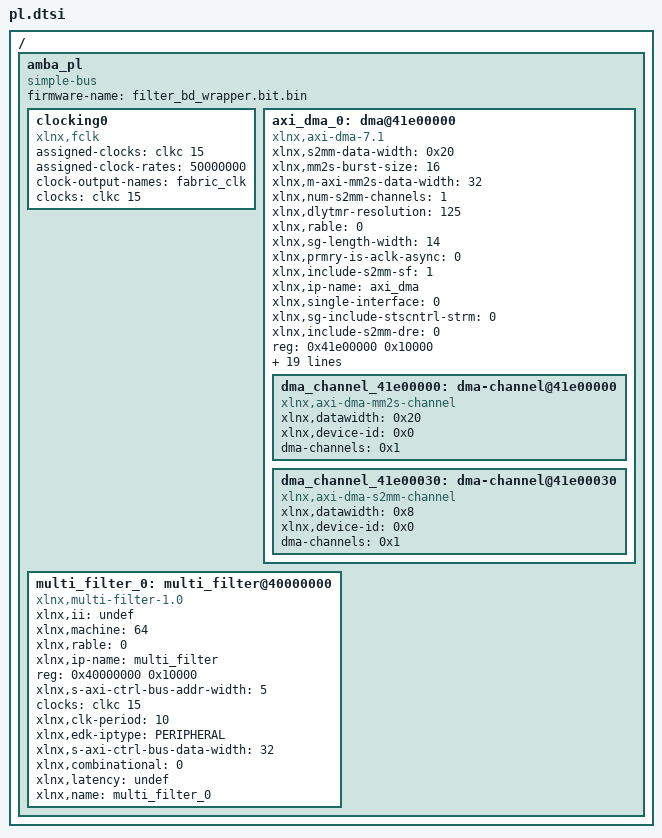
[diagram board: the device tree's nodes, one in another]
/ {
	amba_pl: amba_pl {
		ranges;
		compatible = "simple-bus";
		#address-cells = <1>;
		#size-cells = <1>;
		firmware-name = "filter_bd_wrapper.bit.bin";
		clocking0: clocking0 {
			compatible = "xlnx,fclk";
			assigned-clocks = <&clkc 15>;
			assigned-clock-rates = <50000000>;
			#clock-cells = <0>;
			clock-output-names = "fabric_clk";
			clocks = <&clkc 15>;
		};
		axi_dma_0: dma@41e00000 {
			compatible = "xlnx,axi-dma-7.1" , "xlnx,axi-dma-1.00.a";
			xlnx,s2mm-data-width = <0x20>;
			xlnx,mm2s-burst-size = <16>;
			xlnx,m-axi-mm2s-data-width = <32>;
			xlnx,num-s2mm-channels = <1>;
			xlnx,dlytmr-resolution = <125>;
			xlnx,rable = <0>;
			xlnx,sg-length-width = <14>;
			xlnx,prmry-is-aclk-async = <0>;
			xlnx,include-s2mm-sf = <1>;
			#dma-cells = <1>;
			xlnx,ip-name = "axi_dma";
			xlnx,single-interface = <0>;
			xlnx,sg-include-stscntrl-strm = <0>;
			xlnx,include-s2mm-dre = <0>;
			reg = <0x41e00000 0x10000>;
			xlnx,addr-width = <32>;
			xlnx,include-s2mm = <1>;
			clocks = <&clkc 15>, <&clkc 15>, <&clkc 15>;
			xlnx,s-axis-s2mm-tdata-width = <8>;
			xlnx,micro-dma = <0>;
			xlnx,increase-throughput = <0>;
			xlnx,mm2s-data-width = <0x20>;
			xlnx,addrwidth = <0x20>;
			xlnx,sg-use-stsapp-length = <0>;
			xlnx,m-axis-mm2s-tdata-width = <8>;
			xlnx,edk-iptype = "PERIPHERAL";
			xlnx,s2mm-burst-size = <16>;
			xlnx,m-axi-s2mm-data-width = <32>;
			xlnx,num-mm2s-channels = <1>;
			xlnx,enable-multi-channel = <0>;
			status = "okay";
			xlnx,include-mm2s-sf = <1>;
			clock-names = "m_axi_mm2s_aclk" , "m_axi_s2mm_aclk" , "s_axi_lite_aclk";
			xlnx,include-mm2s = <1>;
			xlnx,include-mm2s-dre = <0>;
			xlnx,name = "axi_dma_0";
			dma_channel_41e00000: dma-channel@41e00000 {
				xlnx,datawidth = <0x20>;
				xlnx,device-id = <0x0>;
				compatible = "xlnx,axi-dma-mm2s-channel";
				dma-channels = <0x1>;
			};
			dma_channel_41e00030: dma-channel@41e00030 {
				xlnx,datawidth = <0x8>;
				xlnx,device-id = <0x0>;
				compatible = "xlnx,axi-dma-s2mm-channel";
				dma-channels = <0x1>;
			};
		};
		multi_filter_0: multi_filter@40000000 {
			compatible = "xlnx,multi-filter-1.0";
			xlnx,ii = "undef";
			xlnx,machine = <64>;
			xlnx,rable = <0>;
			xlnx,ip-name = "multi_filter";
			reg = <0x40000000 0x10000>;
			xlnx,s-axi-ctrl-bus-addr-width = <5>;
			clocks = <&clkc 15>;
			xlnx,clk-period = <10>;
			xlnx,edk-iptype = "PERIPHERAL";
			status = "okay";
			clock-names = "ap_clk";
			xlnx,s-axi-ctrl-bus-data-width = <32>;
			xlnx,combinational = <0>;
			xlnx,latency = "undef";
			xlnx,name = "multi_filter_0";
		};
	};
};
